AUTOSAR XML (schema 4-0-3)
package /ComponentTypes
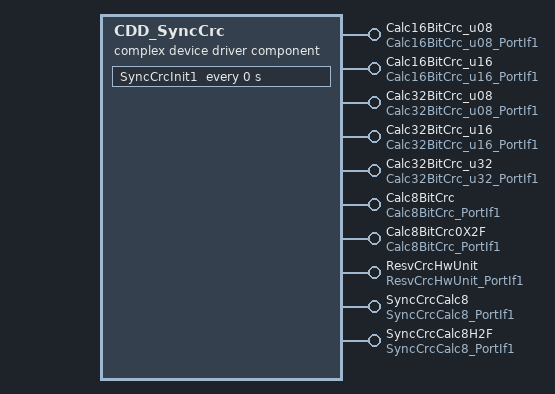
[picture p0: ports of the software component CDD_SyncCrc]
  complex device driver sw component type CDD_SyncCrc
    10 x provide port, all with server-com-spec{operation=Oper, queue-length=1}:
      Calc16BitCrc_u08: provided-interface=Calc16BitCrc_u08_PortIf1
      Calc16BitCrc_u16: provided-interface=Calc16BitCrc_u16_PortIf1
      Calc32BitCrc_u08: provided-interface=Calc32BitCrc_u08_PortIf1
      Calc32BitCrc_u16: provided-interface=Calc32BitCrc_u16_PortIf1
      Calc32BitCrc_u32: provided-interface=Calc32BitCrc_u32_PortIf1
      Calc8BitCrc: provided-interface=Calc8BitCrc_PortIf1
      Calc8BitCrc0X2F: provided-interface=Calc8BitCrc_PortIf1
      ResvCrcHwUnit: provided-interface=ResvCrcHwUnit_PortIf1
      SyncCrcCalc8: provided-interface=SyncCrcCalc8_PortIf1
      SyncCrcCalc8H2F: provided-interface=SyncCrcCalc8_PortIf1
    behavior CDD_SyncCrc_InternalBehavior: data-type-mapping=Nexteer
      exclusive area SyncCrcExclusiveArea
      ar-typed-per-instance-memorys:
        data CrcHwSts: sw-calibration-access=READ-ONLY, type=Ary1D_CrcHwStsRec1_4
      8 x operation invoked event:
        OIT_Calc16BitCrc_u08_Oper_Calc16BitCrc_u08_Oper: start-on-event=Calc16BitCrc_u08_Oper, operation=Calc16BitCrc_u08.Oper
        OIT_Calc16BitCrc_u16_Oper_Calc16BitCrc_u16_Oper: start-on-event=Calc16BitCrc_u16_Oper, operation=Calc16BitCrc_u16.Oper
        OIT_Calc32BitCrc_u08_Oper_Calc32BitCrc_u08_Oper: start-on-event=Calc32BitCrc_u08_Oper, operation=Calc32BitCrc_u08.Oper
        OIT_Calc32BitCrc_u16_Oper_Calc32BitCrc_u16_Oper: start-on-event=Calc32BitCrc_u16_Oper, operation=Calc32BitCrc_u16.Oper
        OIT_Calc32BitCrc_u32_Oper_Calc32BitCrc_u32_Oper: start-on-event=Calc32BitCrc_u32_Oper, operation=Calc32BitCrc_u32.Oper
        OIT_Calc8BitCrc_Oper_Calc8BitCrc_Oper: start-on-event=Calc8BitCrc_Oper, operation=Calc8BitCrc.Oper
        OIT_Calc8BitCrc0X2F_Oper_Calc8BitCrc0X2F_Oper: start-on-event=Calc8BitCrc0X2F_Oper, operation=Calc8BitCrc0X2F.Oper
        OIT_ResvCrcHwUnit_Oper_ResvCrcHwUnit_Oper: start-on-event=ResvCrcHwUnit_Oper, operation=ResvCrcHwUnit.Oper
      timing event SyncCrcInit1_InitEvent: start-on-event=SyncCrcInit1, period=0
      9 x runnable:
        Calc16BitCrc_u08_Oper: can-enter-exclusive-area=SyncCrcExclusiveArea, can-be-invoked-concurrently=true
        Calc16BitCrc_u16_Oper: can-enter-exclusive-area=SyncCrcExclusiveArea, can-be-invoked-concurrently=true
        Calc32BitCrc_u08_Oper: can-enter-exclusive-area=SyncCrcExclusiveArea, can-be-invoked-concurrently=true
        Calc32BitCrc_u16_Oper: can-enter-exclusive-area=SyncCrcExclusiveArea, can-be-invoked-concurrently=true
        Calc32BitCrc_u32_Oper: can-enter-exclusive-area=SyncCrcExclusiveArea, can-be-invoked-concurrently=true
        Calc8BitCrc_Oper: can-enter-exclusive-area=SyncCrcExclusiveArea, can-be-invoked-concurrently=true
        Calc8BitCrc0X2F_Oper: can-enter-exclusive-area=SyncCrcExclusiveArea, can-be-invoked-concurrently=true
        ResvCrcHwUnit_Oper: can-enter-exclusive-area=SyncCrcExclusiveArea, can-be-invoked-concurrently=true
        SyncCrcInit1
  swc implementation CDD_SyncCrc_Implementation: behavior=CDD_SyncCrc_InternalBehavior
    code-descriptors:
      code Default: artifact-descriptors=autosar-engineering-object={short-label=Default, category=SWSRC}
